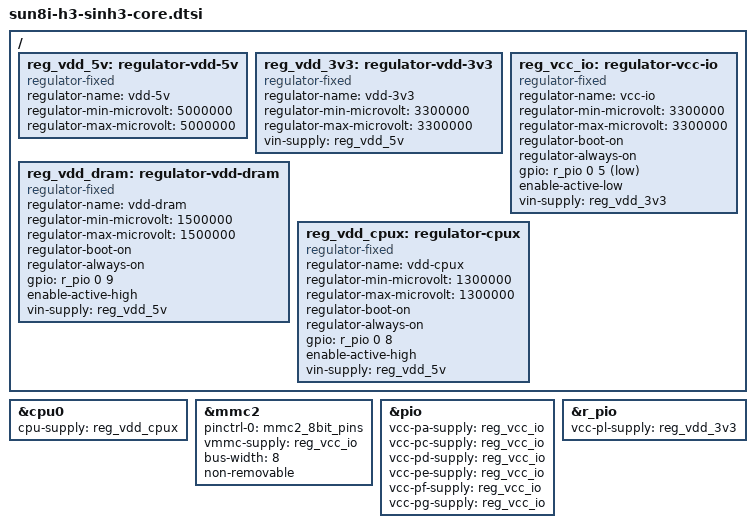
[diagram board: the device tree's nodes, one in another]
/*
 * Copyright (C) 2021 Mans Rullgard <mans@mansr.com>
 *
 * This file is dual-licensed: you can use it either under the terms
 * of the GPL or the X11 license, at your option. Note that this dual
 * licensing only applies to this file, and not this project as a
 * whole.
 *
 *  a) This file is free software; you can redistribute it and/or
 *     modify it under the terms of the GNU General Public License as
 *     published by the Free Software Foundation; either version 2 of the
 *     License, or (at your option) any later version.
 *
 *     This file is distributed in the hope that it will be useful,
 *     but WITHOUT ANY WARRANTY; without even the implied warranty of
 *     MERCHANTABILITY or FITNESS FOR A PARTICULAR PURPOSE.  See the
 *     GNU General Public License for more details.
 *
 * Or, alternatively,
 *
 *  b) Permission is hereby granted, free of charge, to any person
 *     obtaining a copy of this software and associated documentation
 *     files (the "Software"), to deal in the Software without
 *     restriction, including without limitation the rights to use,
 *     copy, modify, merge, publish, distribute, sublicense, and/or
 *     sell copies of the Software, and to permit persons to whom the
 *     Software is furnished to do so, subject to the following
 *     conditions:
 *
 *     The above copyright notice and this permission notice shall be
 *     included in all copies or substantial portions of the Software.
 *
 *     THE SOFTWARE IS PROVIDED "AS IS", WITHOUT WARRANTY OF ANY KIND,
 *     EXPRESS OR IMPLIED, INCLUDING BUT NOT LIMITED TO THE WARRANTIES
 *     OF MERCHANTABILITY, FITNESS FOR A PARTICULAR PURPOSE AND
 *     NONINFRINGEMENT. IN NO EVENT SHALL THE AUTHORS OR COPYRIGHT
 *     HOLDERS BE LIABLE FOR ANY CLAIM, DAMAGES OR OTHER LIABILITY,
 *     WHETHER IN AN ACTION OF CONTRACT, TORT OR OTHERWISE, ARISING
 *     FROM, OUT OF OR IN CONNECTION WITH THE SOFTWARE OR THE USE OR
 *     OTHER DEALINGS IN THE SOFTWARE.
 */

/dts-v1/;
#include "sun8i-h3.dtsi"

#include <dt-bindings/gpio/gpio.h>

/ {
	reg_vdd_5v: regulator-vdd-5v {
		compatible = "regulator-fixed";
		regulator-name = "vdd-5v";
		regulator-min-microvolt = <5000000>;
		regulator-max-microvolt = <5000000>;
	};

	reg_vdd_3v3: regulator-vdd-3v3 {
		compatible = "regulator-fixed";
		regulator-name = "vdd-3v3";
		regulator-min-microvolt = <3300000>;
		regulator-max-microvolt = <3300000>;
		vin-supply = <&reg_vdd_5v>;
	};

	reg_vcc_io: regulator-vcc-io {
		compatible = "regulator-fixed";
		regulator-name = "vcc-io";
		regulator-min-microvolt = <3300000>;
		regulator-max-microvolt = <3300000>;
		regulator-boot-on;
		regulator-always-on;
		gpio = <&r_pio 0 5 GPIO_ACTIVE_LOW>; /* PL5 */
		enable-active-low;
		vin-supply = <&reg_vdd_3v3>;
	};

	reg_vdd_dram: regulator-vdd-dram {
		compatible = "regulator-fixed";
		regulator-name = "vdd-dram";
		regulator-min-microvolt = <1500000>;
		regulator-max-microvolt = <1500000>;
		regulator-boot-on;
		regulator-always-on;
		gpio = <&r_pio 0 9 GPIO_ACTIVE_HIGH>; /* PL9 */
		enable-active-high;
		vin-supply = <&reg_vdd_5v>;
	};

	reg_vdd_cpux: regulator-cpux {
		compatible = "regulator-fixed";
		regulator-name = "vdd-cpux";
		regulator-min-microvolt = <1300000>;
		regulator-max-microvolt = <1300000>;
		regulator-boot-on;
		regulator-always-on;
		gpio = <&r_pio 0 8 GPIO_ACTIVE_HIGH>; /* PL8 */
		enable-active-high;
		vin-supply = <&reg_vdd_5v>;
	};
};

&cpu0 {
	cpu-supply = <&reg_vdd_cpux>;
};

&mmc2 {
	pinctrl-names = "default";
	pinctrl-0 = <&mmc2_8bit_pins>;
	vmmc-supply = <&reg_vcc_io>;
	bus-width = <8>;
	non-removable;
	status = "okay";
};

&pio {
	vcc-pa-supply = <&reg_vcc_io>;
	vcc-pc-supply = <&reg_vcc_io>;
	vcc-pd-supply = <&reg_vcc_io>;
	vcc-pe-supply = <&reg_vcc_io>;
	vcc-pf-supply = <&reg_vcc_io>;
	vcc-pg-supply = <&reg_vcc_io>;
};

&r_pio {
	vcc-pl-supply = <&reg_vdd_3v3>;
};
